# STM32G484VET6 register map
File version: 1.0
Registers are 32-bit, access not given, reset 0x0 unless marked. A register's access mark holds for its fields unless they carry their own. Offsets are from the block's base; [hi:lo] are bit positions; {n}, {i} and the like mark numbered series; 'fields as' and 'values as' point back to an identical list.

## CRS
Base 0x40002000
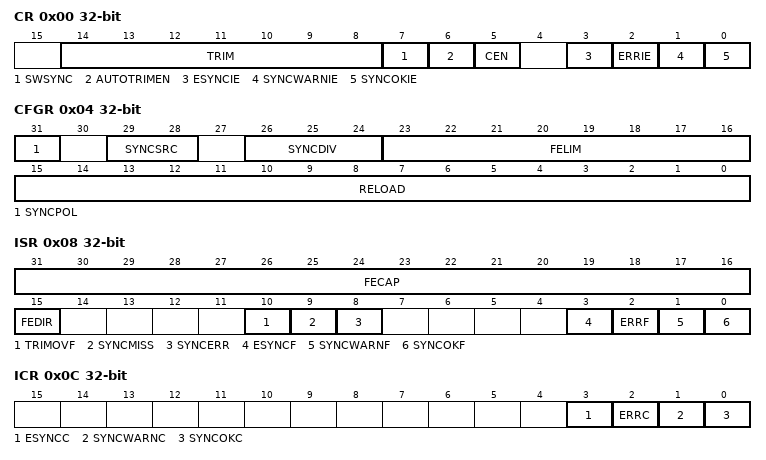
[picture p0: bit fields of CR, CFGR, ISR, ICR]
0x00 CR
  [14:8] TRIM, [7] SWSYNC, [6] AUTOTRIMEN, [5] CEN, [3] ESYNCIE, [2] ERRIE, [1] SYNCWARNIE, [0] SYNCOKIE
0x04 CFGR
  [31] SYNCPOL, [29:28] SYNCSRC, [26:24] SYNCDIV, [23:16] FELIM, [15:0] RELOAD
0x08 ISR
  [31:16] FECAP, [15] FEDIR, [10] TRIMOVF, [9] SYNCMISS, [8] SYNCERR, [3] ESYNCF, [2] ERRF, [1] SYNCWARNF, [0] SYNCOKF
0x0C ICR
  [3] ESYNCC, [2] ERRC, [1] SYNCWARNC, [0] SYNCOKC

## TAMP
Base 0x40002400
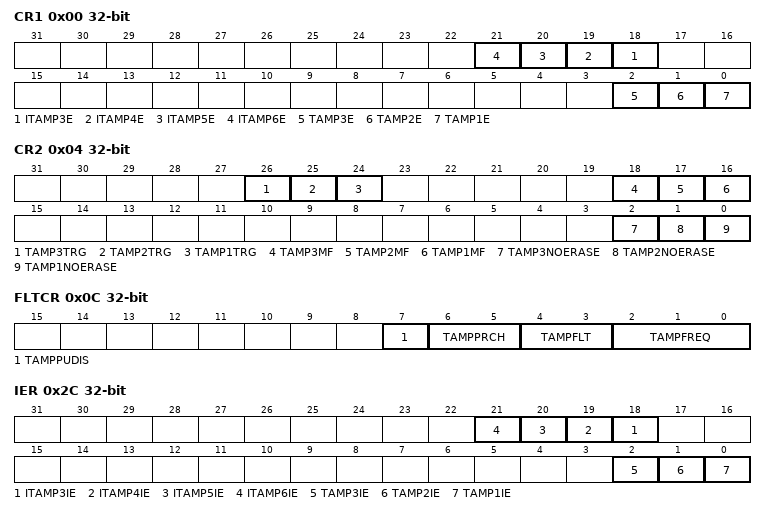
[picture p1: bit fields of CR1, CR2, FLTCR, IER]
0x00 CR1
  [n+15] ITAMP{n}E (n=3..6), [2] TAMP3E, [1] TAMP2E, [0] TAMP1E
0x04 CR2
  [26] TAMP3TRG, [25] TAMP2TRG, [24] TAMP1TRG, [18] TAMP3MF, [17] TAMP2MF, [16] TAMP1MF, [2] TAMP3NOERASE, [1] TAMP2NOERASE, [0] TAMP1NOERASE
0x0C FLTCR
  [7] TAMPPUDIS, [6:5] TAMPPRCH, [4:3] TAMPFLT, [2:0] TAMPFREQ
0x2C IER
  [n+15] ITAMP{n}IE (n=3..6), [2] TAMP3IE, [1] TAMP2IE, [0] TAMP1IE
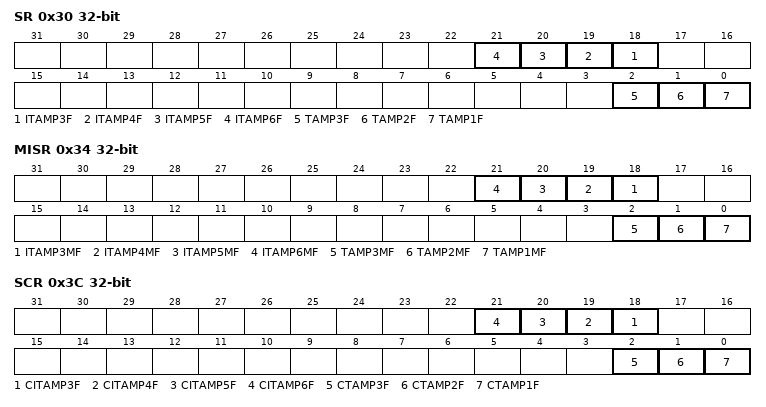
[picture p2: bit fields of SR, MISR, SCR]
0x30 SR
  [n+15] ITAMP{n}F (n=3..6), [2] TAMP3F, [1] TAMP2F, [0] TAMP1F
0x34 MISR
  [n+15] ITAMP{n}MF (n=3..6), [2] TAMP3MF, [1] TAMP2MF, [0] TAMP1MF
0x3C SCR
  [n+15] CITAMP{n}F (n=3..6), [2] CTAMP3F, [1] CTAMP2F, [0] CTAMP1F
{0x100+4i} BKP{i}R (i=0..31)

## RTC
Base 0x40002800
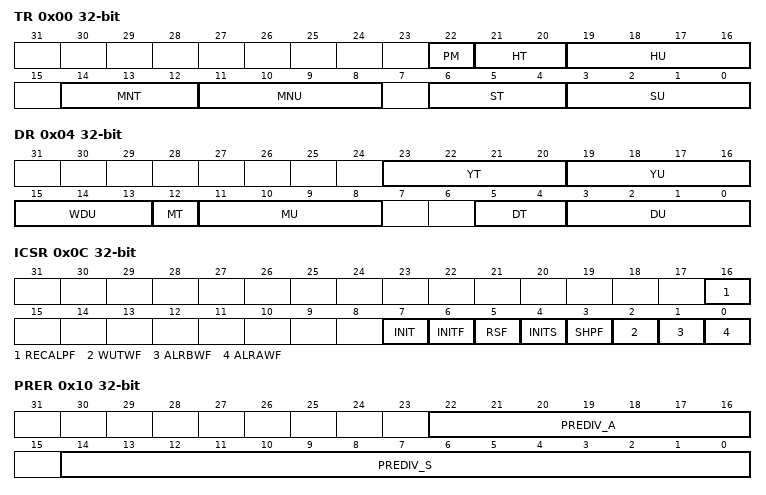
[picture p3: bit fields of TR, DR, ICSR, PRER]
0x00 TR
  [22] PM, [21:20] HT, [19:16] HU, [14:12] MNT, [11:8] MNU, [6:4] ST, [3:0] SU
0x04 DR
  [23:20] YT, [19:16] YU, [15:13] WDU, [12] MT, [11:8] MU, [5:4] DT, [3:0] DU
0x08 SSR
  [15:0] SS
0x0C ICSR
  [16] RECALPF, [7] INIT, [6] INITF, [5] RSF, [4] INITS, [3] SHPF, [2] WUTWF, [1] ALRBWF, [0] ALRAWF
0x10 PRER
  [22:16] PREDIV_A, [14:0] PREDIV_S
0x14 WUTR
  [15:0] WUT
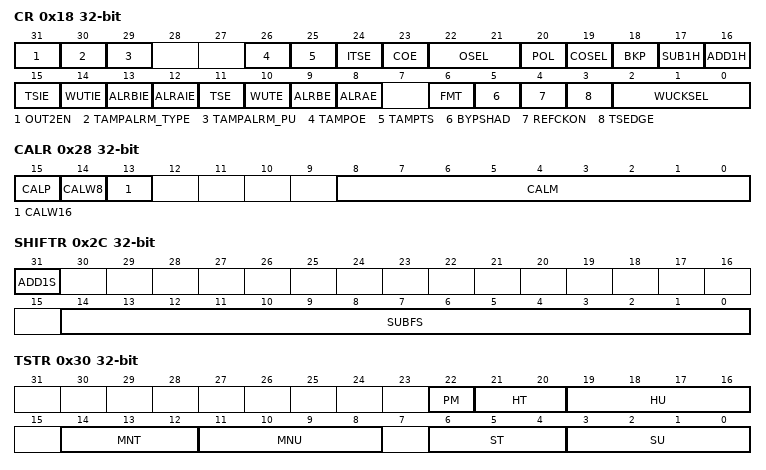
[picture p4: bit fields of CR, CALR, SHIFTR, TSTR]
0x18 CR
  [31] OUT2EN, [30] TAMPALRM_TYPE, [29] TAMPALRM_PU, [26] TAMPOE, [25] TAMPTS, [24] ITSE, [23] COE, [22:21] OSEL, [20] POL, [19] COSEL, [18] BKP, [17] SUB1H, [16] ADD1H, [15] TSIE, [14] WUTIE, [13] ALRBIE, [12] ALRAIE, [11] TSE, [10] WUTE, [9] ALRBE, [8] ALRAE, [6] FMT, [5] BYPSHAD, [4] REFCKON, [3] TSEDGE, [2:0] WUCKSEL
0x24 WPR
  [7:0] KEY
0x28 CALR
  [15] CALP, [14] CALW8, [13] CALW16, [8:0] CALM
0x2C SHIFTR
  [31] ADD1S, [14:0] SUBFS
0x30 TSTR
  fields as TR
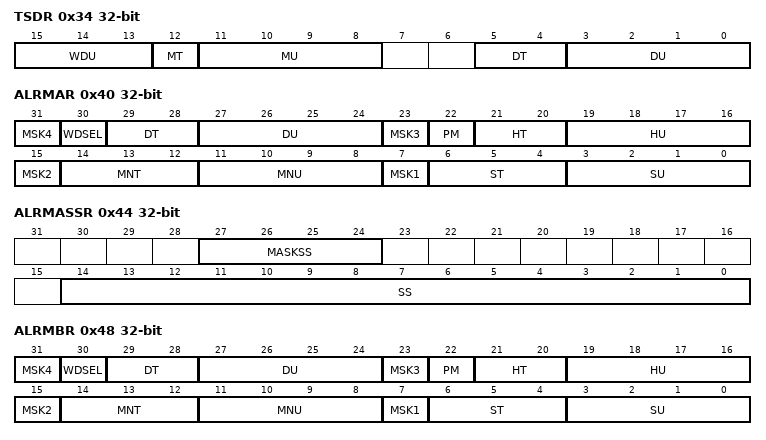
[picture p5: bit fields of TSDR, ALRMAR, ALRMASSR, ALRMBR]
0x34 TSDR
  [15:13] WDU, [12] MT, [11:8] MU, [5:4] DT, [3:0] DU
0x38 TSSSR
  [15:0] SS
0x40 ALRMAR
  [8n-1] MSK{n} (n=1..4), [30] WDSEL, [29:28] DT, [27:24] DU, [22] PM, [21:20] HT, [19:16] HU, [14:12] MNT, [11:8] MNU, [6:4] ST, [3:0] SU
0x44 ALRMASSR
  [27:24] MASKSS, [14:0] SS
0x48 ALRMBR
  fields as ALRMAR
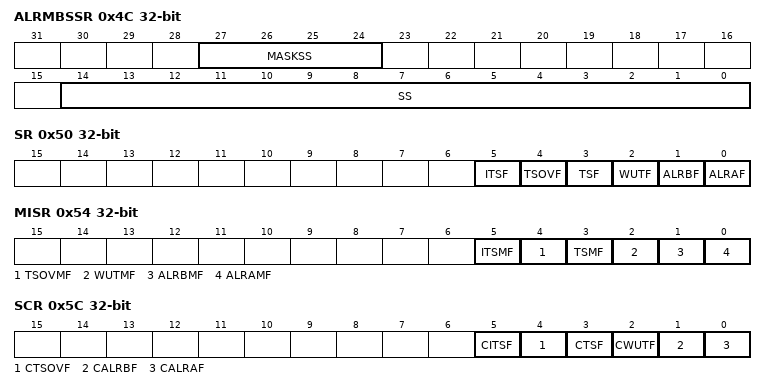
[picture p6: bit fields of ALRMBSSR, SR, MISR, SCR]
0x4C ALRMBSSR
  [27:24] MASKSS, [14:0] SS
0x50 SR
  [5] ITSF, [4] TSOVF, [3] TSF, [2] WUTF, [1] ALRBF, [0] ALRAF
0x54 MISR
  [5] ITSMF, [4] TSOVMF, [3] TSMF, [2] WUTMF, [1] ALRBMF, [0] ALRAMF
0x5C SCR
  [5] CITSF, [4] CTSOVF, [3] CTSF, [2] CWUTF, [1] CALRBF, [0] CALRAF

## WWDG
Base 0x40002C00
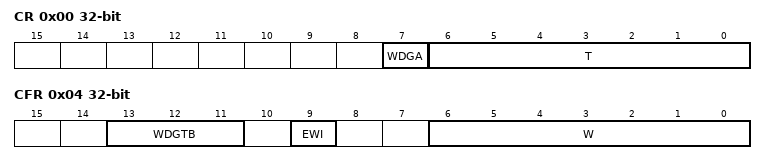
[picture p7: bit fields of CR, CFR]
0x00 CR
  [7] WDGA, [6:0] T
0x04 CFR
  [13:11] WDGTB, [9] EWI, [6:0] W
0x08 SR
  [0] EWIF

## IWDG
Base 0x40003000
0x00 KR
  [15:0] KEY
0x04 PR
  [2:0] PR
0x08 RLR
  [11:0] RL
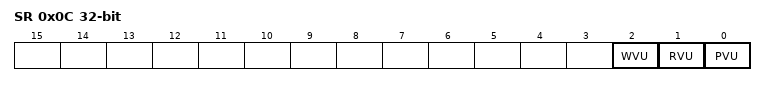
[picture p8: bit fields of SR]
0x0C SR
  [2] WVU, [1] RVU, [0] PVU
0x10 WINR
  [11:0] WIN

## SPI2
Base 0x40003800
Same registers: SPI3 0x40003C00, SPI1 0x40013000, SPI4 0x40013C00
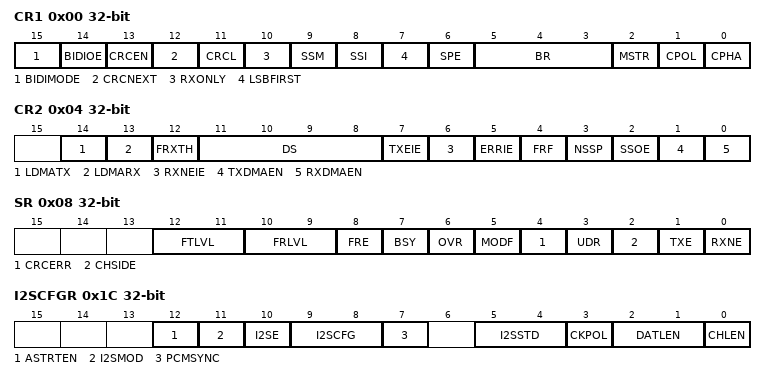
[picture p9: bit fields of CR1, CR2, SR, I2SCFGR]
0x00 CR1
  [15] BIDIMODE, [14] BIDIOE, [13] CRCEN, [12] CRCNEXT, [11] CRCL, [10] RXONLY, [9] SSM, [8] SSI, [7] LSBFIRST, [6] SPE, [5:3] BR, [2] MSTR, [1] CPOL, [0] CPHA
0x04 CR2
  [14] LDMATX, [13] LDMARX, [12] FRXTH, [11:8] DS, [7] TXEIE, [6] RXNEIE, [5] ERRIE, [4] FRF, [3] NSSP, [2] SSOE, [1] TXDMAEN, [0] RXDMAEN
0x08 SR
  [12:11] FTLVL, [10:9] FRLVL, [8] FRE, [7] BSY, [6] OVR, [5] MODF, [4] CRCERR, [3] UDR, [2] CHSIDE, [1] TXE, [0] RXNE
0x0C DR
  [15:0] DR
0x10 CRCPR
  [15:0] CRCPOLY
0x14 RXCRCR
  [15:0] RXCRC
0x18 TXCRCR
  [15:0] TXCRC
0x1C I2SCFGR
  [12] ASTRTEN, [11] I2SMOD, [10] I2SE, [9:8] I2SCFG, [7] PCMSYNC, [5:4] I2SSTD, [3] CKPOL, [2:1] DATLEN, [0] CHLEN
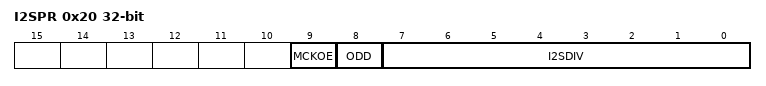
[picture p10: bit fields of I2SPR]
0x20 I2SPR
  [9] MCKOE, [8] ODD, [7:0] I2SDIV

## USART2
Base 0x40004400
Same registers: USART3 0x40004800, UART4 0x40004C00, UART5 0x40005000, LPUART1 0x40008000, USART1 0x40013800
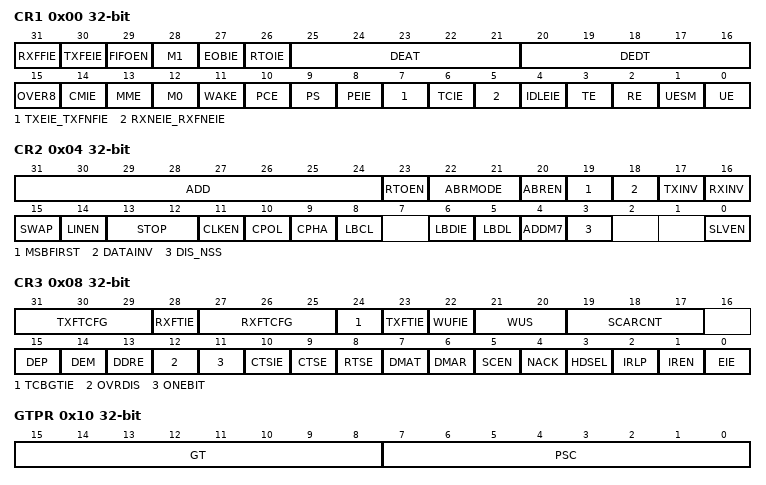
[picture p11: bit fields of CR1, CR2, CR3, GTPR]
0x00 CR1
  [31] RXFFIE, [30] TXFEIE, [29] FIFOEN, [28] M1, [27] EOBIE, [26] RTOIE, [25:21] DEAT, [20:16] DEDT, [15] OVER8, [14] CMIE, [13] MME, [12] M0, [11] WAKE, [10] PCE, [9] PS, [8] PEIE, [7] TXEIE_TXFNFIE, [6] TCIE, [5] RXNEIE_RXFNEIE, [4] IDLEIE, [3] TE, [2] RE, [1] UESM, [0] UE
0x04 CR2
  [31:24] ADD, [23] RTOEN, [22:21] ABRMODE, [20] ABREN, [19] MSBFIRST, [18] DATAINV, [17] TXINV, [16] RXINV, [15] SWAP, [14] LINEN, [13:12] STOP, [11] CLKEN, [10] CPOL, [9] CPHA, [8] LBCL, [6] LBDIE, [5] LBDL, [4] ADDM7, [3] DIS_NSS, [0] SLVEN
0x08 CR3
  [31:29] TXFTCFG, [28] RXFTIE, [27:25] RXFTCFG, [24] TCBGTIE, [23] TXFTIE, [22] WUFIE, [21:20] WUS, [19:17] SCARCNT, [15] DEP, [14] DEM, [13] DDRE, [12] OVRDIS, [11] ONEBIT, [10] CTSIE, [9] CTSE, [8] RTSE, [7] DMAT, [6] DMAR, [5] SCEN, [4] NACK, [3] HDSEL, [2] IRLP, [1] IREN, [0] EIE
0x0C BRR
  [19:0] LPUART
0x10 GTPR
  [15:8] GT, [7:0] PSC
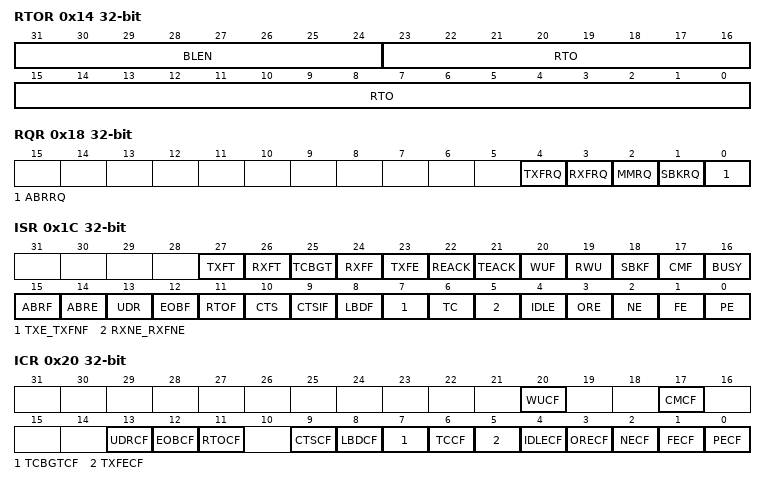
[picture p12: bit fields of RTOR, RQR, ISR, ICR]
0x14 RTOR
  [31:24] BLEN, [23:0] RTO
0x18 RQR
  [4] TXFRQ, [3] RXFRQ, [2] MMRQ, [1] SBKRQ, [0] ABRRQ
0x1C ISR
  [27] TXFT, [26] RXFT, [25] TCBGT, [24] RXFF, [23] TXFE, [22] REACK, [21] TEACK, [20] WUF, [19] RWU, [18] SBKF, [17] CMF, [16] BUSY, [15] ABRF, [14] ABRE, [13] UDR, [12] EOBF, [11] RTOF, [10] CTS, [9] CTSIF, [8] LBDF, [7] TXE_TXFNF, [6] TC, [5] RXNE_RXFNE, [4] IDLE, [3] ORE, [2] NE, [1] FE, [0] PE
0x20 ICR
  [20] WUCF, [17] CMCF, [13] UDRCF, [12] EOBCF, [11] RTOCF, [9] CTSCF, [8] LBDCF, [7] TCBGTCF, [6] TCCF, [5] TXFECF, [4] IDLECF, [3] ORECF, [2] NECF, [1] FECF, [0] PECF
0x24 RDR
  [8:0] RDR
0x28 TDR
  [8:0] TDR
0x2C PRESC
  [3:0] PRESCALER
